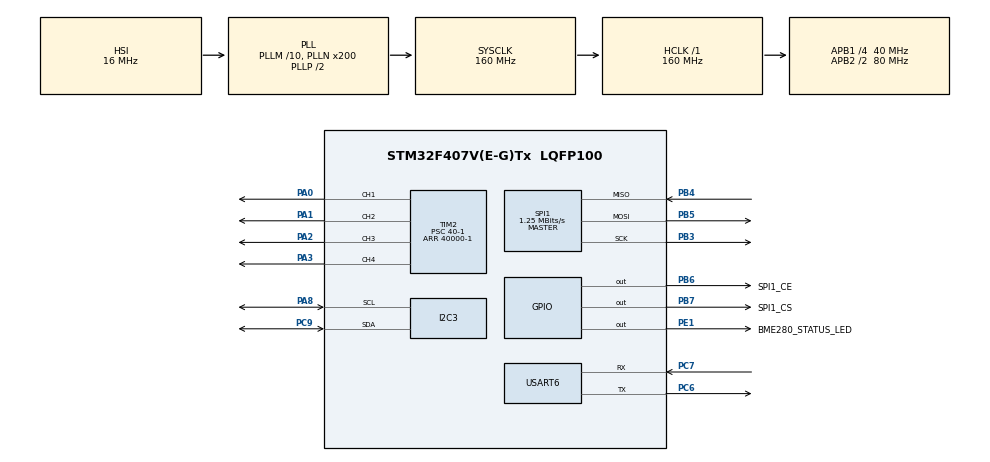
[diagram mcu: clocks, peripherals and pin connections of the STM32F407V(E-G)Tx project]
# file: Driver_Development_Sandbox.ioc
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Mcu.Family=STM32F4
Mcu.Name=STM32F407V(E-G)Tx
Mcu.Package=LQFP100
NVIC.PriorityGroup=NVIC_PRIORITYGROUP_4
NVIC.TIM6_DAC_IRQn=true\:0\:0\:false\:false\:true\:true\:true
PA0-WKUP.Signal=S_TIM2_CH1_ETR
PA1.Signal=S_TIM2_CH2
PA13.Mode=Serial_Wire
PA13.Signal=SYS_JTMS-SWDIO
PA14.Mode=Serial_Wire
PA14.Signal=SYS_JTCK-SWCLK
PA2.Signal=S_TIM2_CH3
PA3.Signal=S_TIM2_CH4
PA8.Mode=I2C
PA8.Signal=I2C3_SCL
PB3.Mode=Full_Duplex_Master
PB3.Signal=SPI1_SCK
PB4.Mode=Full_Duplex_Master
PB4.Signal=SPI1_MISO
PB5.Mode=Full_Duplex_Master
PB5.Signal=SPI1_MOSI
PB6.GPIO_Label=SPI1_CE
PB6.Signal=GPIO_Output
PB7.GPIO_Label=SPI1_CS
PB7.Signal=GPIO_Output
PC6.Mode=Asynchronous
PC6.Signal=USART6_TX
PC7.Mode=Asynchronous
PC7.Signal=USART6_RX
PC9.Mode=I2C
PC9.Signal=I2C3_SDA
PE1.GPIO_Label=BME280_STATUS_LED
PE1.Signal=GPIO_Output
ProjectManager.HeapSize=0x200
ProjectManager.StackSize=0x400
ProjectManager.TargetToolchain=SW4STM32
RCC.48MHZClocksFreq_Value=80000000
RCC.AHBFreq_Value=160000000
RCC.APB1CLKDivider=RCC_HCLK_DIV4
RCC.APB1Freq_Value=40000000
RCC.APB1TimFreq_Value=80000000
RCC.APB2CLKDivider=RCC_HCLK_DIV2
RCC.APB2Freq_Value=80000000
RCC.APB2TimFreq_Value=160000000
RCC.CortexFreq_Value=160000000
RCC.HCLKFreq_Value=160000000
RCC.HSE_VALUE=25000000
RCC.HSI_VALUE=16000000
RCC.LSE_VALUE=32768
RCC.PLLM=10
RCC.PLLN=200
RCC.SYSCLKFreq_VALUE=160000000
RCC.SYSCLKSource=RCC_SYSCLKSOURCE_PLLCLK
RCC.VCOOutputFreq_Value=320000000
SH.S_TIM2_CH1_ETR.0=TIM2_CH1,PWM Generation1 CH1
SH.S_TIM2_CH2.0=TIM2_CH2,PWM Generation2 CH2
SH.S_TIM2_CH3.0=TIM2_CH3,PWM Generation3 CH3
SH.S_TIM2_CH4.0=TIM2_CH4,PWM Generation4 CH4
SPI1.BaudRatePrescaler=SPI_BAUDRATEPRESCALER_64
SPI1.CalculateBaudRate=1.25 MBits/s
SPI1.Direction=SPI_DIRECTION_2LINES
SPI1.Mode=SPI_MODE_MASTER
SPI1.VirtualType=VM_MASTER
TIM2.Channel-PWM\ Generation1\ CH1=TIM_CHANNEL_1
TIM2.Channel-PWM\ Generation2\ CH2=TIM_CHANNEL_2
TIM2.Channel-PWM\ Generation3\ CH3=TIM_CHANNEL_3
TIM2.Channel-PWM\ Generation4\ CH4=TIM_CHANNEL_4
TIM2.Period=40000-1
TIM2.Prescaler=40-1
TIM2.Pulse-PWM\ Generation1\ CH1=500
TIM2.Pulse-PWM\ Generation2\ CH2=600
TIM2.Pulse-PWM\ Generation3\ CH3=700
TIM2.Pulse-PWM\ Generation4\ CH4=800
TIM6.AutoReloadPreload=TIM_AUTORELOAD_PRELOAD_ENABLE
TIM6.Period=1000
TIM6.Prescaler=32000
USART6.VirtualMode=VM_ASYNC
VP_TIM6_VS_ClockSourceINT.Mode=Enable_Timer
board=custom

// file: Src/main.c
/* USER CODE BEGIN Header */
/**
  ******************************************************************************
  * @file           : main.c
  * @brief          : Main program body
  ******************************************************************************
  * @attention
  *
  * <h2><center>&copy; Copyright (c) 2020 STMicroelectronics.
  * All rights reserved.</center></h2>
  *
  * This software component is licensed by ST under BSD 3-Clause license,
  * the "License"; You may not use this file except in compliance with the
  * License. You may obtain a copy of the License at:
  *                        opensource.org/licenses/BSD-3-Clause
  *
  ******************************************************************************
  */
/* USER CODE END Header */

#include "main.h"
#include "i2c.h"
#include "spi.h"
#include "tim.h"
#include "usart.h"
#include "gpio.h"

/* USER CODE BEGIN Includes */
#include "flightControl.h"
#include "MY_NRF24.h"
#include "bme280.h"
#include "logging.h"
/* USER CODE END Includes */

void SystemClock_Config(void);

int main(void)
{

  /* MCU Configuration--------------------------------------------------------*/

  /* Reset of all peripherals, Initializes the Flash interface and the Systick. */
  HAL_Init();

  /* Configure the system clock */
  SystemClock_Config();

  /* Initialize all configured peripherals */
  MX_GPIO_Init();
  MX_SPI1_Init();
  MX_I2C3_Init();
  MX_USART6_UART_Init();
  MX_TIM2_Init();
  MX_TIM6_Init();

  /* Infinite loop */
  /* USER CODE BEGIN WHILE */
  FC_Init();
  HAL_Delay(2000); // is this necessary?
  FC_Flight_Loop();

  while (1)
  {
    /*THIS SECTION SHOULD NOT BE REACHED */

    /* USER CODE END WHILE */

  }
}

void SystemClock_Config(void)
{
  RCC_OscInitTypeDef RCC_OscInitStruct = {0};
  RCC_ClkInitTypeDef RCC_ClkInitStruct = {0};

  /** Configure the main internal regulator output voltage
  */
  __HAL_RCC_PWR_CLK_ENABLE();
  __HAL_PWR_VOLTAGESCALING_CONFIG(PWR_REGULATOR_VOLTAGE_SCALE1);
  /** Initializes the CPU, AHB and APB busses clocks
  */
  RCC_OscInitStruct.OscillatorType = RCC_OSCILLATORTYPE_HSI;
  RCC_OscInitStruct.HSIState = RCC_HSI_ON;
  RCC_OscInitStruct.HSICalibrationValue = RCC_HSICALIBRATION_DEFAULT;
  RCC_OscInitStruct.PLL.PLLState = RCC_PLL_ON;
  RCC_OscInitStruct.PLL.PLLSource = RCC_PLLSOURCE_HSI;
  RCC_OscInitStruct.PLL.PLLM = 10;
  RCC_OscInitStruct.PLL.PLLN = 200;
  RCC_OscInitStruct.PLL.PLLP = RCC_PLLP_DIV2;
  RCC_OscInitStruct.PLL.PLLQ = 4;
  if (HAL_RCC_OscConfig(&RCC_OscInitStruct) != HAL_OK)
  {
    Error_Handler();
  }
  /** Initializes the CPU, AHB and APB busses clocks
  */
  RCC_ClkInitStruct.ClockType = RCC_CLOCKTYPE_HCLK|RCC_CLOCKTYPE_SYSCLK
                              |RCC_CLOCKTYPE_PCLK1|RCC_CLOCKTYPE_PCLK2;
  RCC_ClkInitStruct.SYSCLKSource = RCC_SYSCLKSOURCE_PLLCLK;
  RCC_ClkInitStruct.AHBCLKDivider = RCC_SYSCLK_DIV1;
  RCC_ClkInitStruct.APB1CLKDivider = RCC_HCLK_DIV4;
  RCC_ClkInitStruct.APB2CLKDivider = RCC_HCLK_DIV2;

  if (HAL_RCC_ClockConfig(&RCC_ClkInitStruct, FLASH_LATENCY_5) != HAL_OK)
  {
    Error_Handler();
  }
}

void Error_Handler(void)
{
}

/************************ (C) COPYRIGHT STMicroelectronics *****END OF FILE****/
